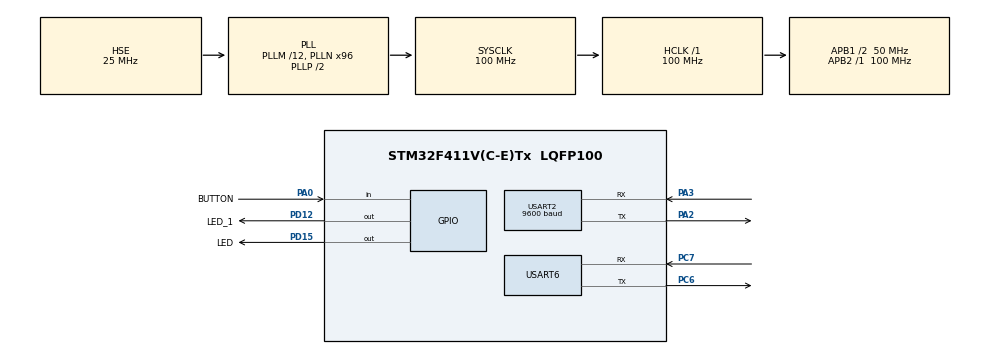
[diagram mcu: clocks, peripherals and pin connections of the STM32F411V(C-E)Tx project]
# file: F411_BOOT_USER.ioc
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Mcu.Family=STM32F4
Mcu.Name=STM32F411V(C-E)Tx
Mcu.Package=LQFP100
NVIC.PriorityGroup=NVIC_PRIORITYGROUP_4
PA0-WKUP.GPIO_Label=BUTTON
PA0-WKUP.Signal=GPIO_Input
PA13.Mode=Serial_Wire
PA13.Signal=SYS_JTMS-SWDIO
PA14.Mode=Serial_Wire
PA14.Signal=SYS_JTCK-SWCLK
PA2.Mode=Asynchronous
PA2.Signal=USART2_TX
PA3.Mode=Asynchronous
PA3.Signal=USART2_RX
PC6.Mode=Asynchronous
PC6.Signal=USART6_TX
PC7.Mode=Asynchronous
PC7.Signal=USART6_RX
PD12.GPIO_Label=LED_1
PD12.Signal=GPIO_Output
PD15.GPIO_Label=LED
PD15.Signal=GPIO_Output
PH0\ -\ OSC_IN.Mode=HSE-External-Oscillator
PH0\ -\ OSC_IN.Signal=RCC_OSC_IN
PH1\ -\ OSC_OUT.Mode=HSE-External-Oscillator
PH1\ -\ OSC_OUT.Signal=RCC_OSC_OUT
ProjectManager.HeapSize=0x200
ProjectManager.StackSize=0x400
ProjectManager.TargetToolchain=STM32CubeIDE
RCC.48MHZClocksFreq_Value=50000000
RCC.AHBFreq_Value=100000000
RCC.APB1CLKDivider=RCC_HCLK_DIV2
RCC.APB1Freq_Value=50000000
RCC.APB1TimFreq_Value=100000000
RCC.APB2Freq_Value=100000000
RCC.APB2TimFreq_Value=100000000
RCC.CortexFreq_Value=100000000
RCC.HCLKFreq_Value=100000000
RCC.HSE_VALUE=25000000
RCC.HSI_VALUE=16000000
RCC.LSE_VALUE=32768
RCC.PLLM=12
RCC.PLLN=96
RCC.PLLSourceVirtual=RCC_PLLSOURCE_HSE
RCC.SYSCLKFreq_VALUE=100000000
RCC.SYSCLKSource=RCC_SYSCLKSOURCE_PLLCLK
RCC.VCOOutputFreq_Value=200000000
USART2.BaudRate=9600
USART2.VirtualMode=VM_ASYNC
USART6.VirtualMode=VM_ASYNC
VP_CRC_VS_CRC.Mode=CRC_Activate
board=custom

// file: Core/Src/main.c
/* USER CODE BEGIN Header */
/**
  ******************************************************************************
  * @file           : main.c
  * @brief          : Main program body
  ******************************************************************************
  * @attention
  *
  * Copyright (c) 2024 STMicroelectronics.
  * All rights reserved.
  *
  * This software is licensed under terms that can be found in the LICENSE file
  * in the root directory of this software component.
  * If no LICENSE file comes with this software, it is provided AS-IS.
  *
  ******************************************************************************
  */
/* USER CODE END Header */
#include "main.h"

/* USER CODE BEGIN Includes */
#define APP_ADDRESS 0x08040000UL
#define RESET_OFFSET 0x04
/* USER CODE END Includes */

CRC_HandleTypeDef hcrc;

UART_HandleTypeDef huart2;
UART_HandleTypeDef huart6;

void SystemClock_Config(void);
static void MX_GPIO_Init(void);
static void MX_USART2_UART_Init(void);
static void MX_USART6_UART_Init(void);
static void MX_CRC_Init(void);
/* USER CODE BEGIN PFP */
void user_aplication_code(void);
extern void boot_main();
/* USER CODE END PFP */

int main(void)
{

  /* MCU Configuration--------------------------------------------------------*/

  /* Reset of all peripherals, Initializes the Flash interface and the Systick. */
  HAL_Init();

  /* Configure the system clock */
  SystemClock_Config();

  /* Initialize all configured peripherals */
  MX_GPIO_Init();
  MX_USART2_UART_Init();
  MX_USART6_UART_Init();
  MX_CRC_Init();
  /* USER CODE BEGIN 2 */
  if(HAL_GPIO_ReadPin(BUTTON_GPIO_Port, BUTTON_Pin) == 1)
  {
	  user_aplication_code();
  }
  /* USER CODE END 2 */

  /* Infinite loop */
  /* USER CODE BEGIN WHILE */
  while (1)
  {
	  boot_main();
    /* USER CODE END WHILE */

  }
}

void SystemClock_Config(void)
{
  RCC_OscInitTypeDef RCC_OscInitStruct = {0};
  RCC_ClkInitTypeDef RCC_ClkInitStruct = {0};

  /** Configure the main internal regulator output voltage
  */
  __HAL_RCC_PWR_CLK_ENABLE();
  __HAL_PWR_VOLTAGESCALING_CONFIG(PWR_REGULATOR_VOLTAGE_SCALE1);

  /** Initializes the RCC Oscillators according to the specified parameters
  * in the RCC_OscInitTypeDef structure.
  */
  RCC_OscInitStruct.OscillatorType = RCC_OSCILLATORTYPE_HSE;
  RCC_OscInitStruct.HSEState = RCC_HSE_ON;
  RCC_OscInitStruct.PLL.PLLState = RCC_PLL_ON;
  RCC_OscInitStruct.PLL.PLLSource = RCC_PLLSOURCE_HSE;
  RCC_OscInitStruct.PLL.PLLM = 12;
  RCC_OscInitStruct.PLL.PLLN = 96;
  RCC_OscInitStruct.PLL.PLLP = RCC_PLLP_DIV2;
  RCC_OscInitStruct.PLL.PLLQ = 4;
  if (HAL_RCC_OscConfig(&RCC_OscInitStruct) != HAL_OK)
  {
    Error_Handler();
  }

  /** Initializes the CPU, AHB and APB buses clocks
  */
  RCC_ClkInitStruct.ClockType = RCC_CLOCKTYPE_HCLK|RCC_CLOCKTYPE_SYSCLK
                              |RCC_CLOCKTYPE_PCLK1|RCC_CLOCKTYPE_PCLK2;
  RCC_ClkInitStruct.SYSCLKSource = RCC_SYSCLKSOURCE_PLLCLK;
  RCC_ClkInitStruct.AHBCLKDivider = RCC_SYSCLK_DIV1;
  RCC_ClkInitStruct.APB1CLKDivider = RCC_HCLK_DIV2;
  RCC_ClkInitStruct.APB2CLKDivider = RCC_HCLK_DIV1;

  if (HAL_RCC_ClockConfig(&RCC_ClkInitStruct, FLASH_LATENCY_3) != HAL_OK)
  {
    Error_Handler();
  }
}

static void MX_CRC_Init(void)
{

  hcrc.Instance = CRC;
  if (HAL_CRC_Init(&hcrc) != HAL_OK)
  {
    Error_Handler();
  }

}

static void MX_USART2_UART_Init(void)
{

  huart2.Instance = USART2;
  huart2.Init.BaudRate = 9600;
  huart2.Init.WordLength = UART_WORDLENGTH_8B;
  huart2.Init.StopBits = UART_STOPBITS_1;
  huart2.Init.Parity = UART_PARITY_NONE;
  huart2.Init.Mode = UART_MODE_TX_RX;
  huart2.Init.HwFlowCtl = UART_HWCONTROL_NONE;
  huart2.Init.OverSampling = UART_OVERSAMPLING_16;
  if (HAL_UART_Init(&huart2) != HAL_OK)
  {
    Error_Handler();
  }

}

static void MX_USART6_UART_Init(void)
{

  huart6.Instance = USART6;
  huart6.Init.BaudRate = 115200;
  huart6.Init.WordLength = UART_WORDLENGTH_8B;
  huart6.Init.StopBits = UART_STOPBITS_1;
  huart6.Init.Parity = UART_PARITY_NONE;
  huart6.Init.Mode = UART_MODE_TX_RX;
  huart6.Init.HwFlowCtl = UART_HWCONTROL_NONE;
  huart6.Init.OverSampling = UART_OVERSAMPLING_16;
  if (HAL_UART_Init(&huart6) != HAL_OK)
  {
    Error_Handler();
  }

}

static void MX_GPIO_Init(void)
{
  GPIO_InitTypeDef GPIO_InitStruct = {0};

  /* GPIO Ports Clock Enable */
  __HAL_RCC_GPIOH_CLK_ENABLE();
  __HAL_RCC_GPIOA_CLK_ENABLE();
  __HAL_RCC_GPIOD_CLK_ENABLE();
  __HAL_RCC_GPIOC_CLK_ENABLE();

  /*Configure GPIO pin Output Level */
  HAL_GPIO_WritePin(GPIOD, LED_1_Pin|LED_Pin, GPIO_PIN_RESET);

  /*Configure GPIO pin : BUTTON_Pin */
  GPIO_InitStruct.Pin = BUTTON_Pin;
  GPIO_InitStruct.Mode = GPIO_MODE_INPUT;
  GPIO_InitStruct.Pull = GPIO_NOPULL;
  HAL_GPIO_Init(BUTTON_GPIO_Port, &GPIO_InitStruct);

  /*Configure GPIO pins : LED_1_Pin LED_Pin */
  GPIO_InitStruct.Pin = LED_1_Pin|LED_Pin;
  GPIO_InitStruct.Mode = GPIO_MODE_OUTPUT_PP;
  GPIO_InitStruct.Pull = GPIO_NOPULL;
  GPIO_InitStruct.Speed = GPIO_SPEED_FREQ_LOW;
  HAL_GPIO_Init(GPIOD, &GPIO_InitStruct);

}

/* USER CODE BEGIN 4 */
void user_aplication_code()
{
		__set_MSP((uint32_t)APP_ADDRESS);
	void (*Reset_handler)() = *(volatile uint32_t *)(APP_ADDRESS + RESET_OFFSET);
	Reset_handler();
}
/* USER CODE END 4 */

void Error_Handler(void)
{
  __disable_irq();
  while (1)
  {
  }
}
